# PIC32MZ0512EFF144 device description
Architecture: 32xxxx; Family: PIC32MZEF; Series: PIC32MZ
Registers are 32-bit, read-write, no defined reset value unless marked. A register's access mark holds for its fields unless they carry their own. Offsets are from the block's base; [hi:lo] are bit positions; {n}, {i} and the like mark numbered series; 'fields as' and 'values as' point back to an identical list.

## FUSECONFIG
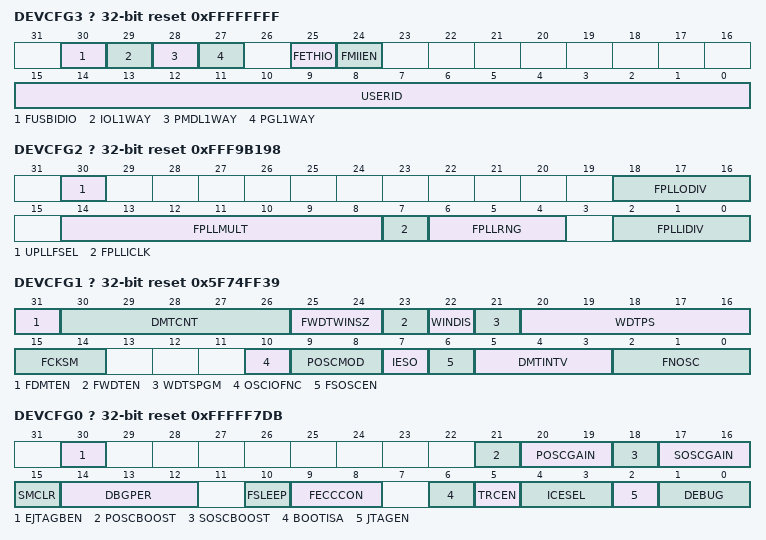
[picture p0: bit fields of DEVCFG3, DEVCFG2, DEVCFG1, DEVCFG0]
? DEVCFG3 size not given access not given reset 0xFFFFFFFF — Device Configuration Word 3
  [30] FUSBIDIO — USB USBID Selection bit
    0=OFF (Controlled by Port Function); 1=ON (Controlled by the USB Module)
  [29] IOL1WAY — Peripheral Pin Select Configuration bit
    1=ON (Allow only one reconfiguration); 0=OFF (Allow multiple reconfigurations)
  [28] PMDL1WAY — Peripheral Module Disable Configuration bit
    values as IOL1WAY
  [27] PGL1WAY — Permission Group Lock One Way Configuration bit
    values as IOL1WAY
  [25] FETHIO — Ethernet I/O Pin Selection Configuration bit
    0=OFF (Alternate Ethernet I/O); 1=ON (Default Ethernet I/O)
  [24] FMIIEN — Ethernet MII Enable Configuration bit
    0=OFF (RMII Enabled); 1=ON (MII Enabled)
  [15:0] USERID
    ?=User ID
? DEVCFG2 size not given access not given reset 0xFFF9B198 — Device Configuration Word 2
  [30] UPLLFSEL — USB PLL Input Frequency Select bit
    1=FREQ_24MHZ (USB PLL input is 24 MHz); 0=FREQ_12MHZ (USB PLL input is 12 MHz)
  [18:16] FPLLODIV — Default System PLL Output Divisor bits
    1=DIV_2 (2x Divider); 2=DIV_4 (4x Divider); 3=DIV_8 (8x Divider); 4=DIV_16 (16x Divider); 7=DIV_32 (32x Divider)
  [14:8] FPLLMULT — System PLL Feedback Divider bits
    {v}=MUL_{v+1} (PLL Multiply by {v+1}) (v=0..127)
  [7] FPLLICLK — System PLL Input Clock Select bit
    1=PLL_FRC (FRC is input to the System PLL); 0=PLL_POSC (POSC is input to the System PLL)
  [6:4] FPLLRNG — System PLL Divided Input Clock Frequency Range bits
    0=RANGE_BYPASS (Bypass); 1=RANGE_5_10_MHZ (5-10 MHz Input); 2=RANGE_8_16_MHZ (8-16 MHz Input); 3=RANGE_13_26_MHZ (13-26 MHz Input); 4=RANGE_21_42_MHZ (21-42 MHz Input); 5=RANGE_34_68_MHZ (34-68 MHz Input)
  [2:0] FPLLIDIV — PLL Input Divider bits
    {v}=DIV_{v+1} ({v+1}x Divider) (v=0..7)
? DEVCFG1 size not given access not given reset 0x5F74FF39 — Device Configuration Word 1
  [31] FDMTEN — Deadman Timer enable bit
    1=ON (Deadman Timer is enabled and cannot be disabled by software); 0=OFF (Deadman Timer is disabled and can be enabled by software)
  [30:26] DMTCNT — Deadman Timer Count Select bits
    0=DMT8 (2^8 (256)); 1=DMT9 (2^9 (512)); 2=DMT10 (2^10 (1024)); 3=DMT11 (2^11 (2048)); 4=DMT12 (2^12 (4096)); 5=DMT13 (2^13 (8192)); 6=DMT14 (2^14 (16384)); 7=DMT15 (2^15 (32768)); 8=DMT16 (2^16 (65536)); 9=DMT17 (2^17 (131072)); 10=DMT18 (2^18 (262144)); 11=DMT19 (2^19 (524288)); 12=DMT20 (2^20 (1048576)); 13=DMT21 (2^21 (2097152)); 14=DMT22 (2^22 (4194304)); 15=DMT23 (2^23 (8388608)); 16=DMT24 (2^24 (16777216)); 17=DMT25 (2^25 (33554432)); 18=DMT26 (2^26 (67108864)); 19=DMT27 (2^27 (134217728)); 20=DMT28 (2^28 (268435456)); 21=DMT29 (2^29 (536870912)); 22=DMT30 (2^30 (1073741824)); 23=DMT31 (2^31 (2147483648))
  [25:24] FWDTWINSZ — Watchdog Timer Window Size bits
    3=WINSZ_25 (Window size is 25%); 2=WINSZ_37 (Window size is 37.5%); 1=WINSZ_50 (Window size is 50%); 0=WINSZ_75 (Window size is 75%)
  [23] FWDTEN — Watchdog Timer Enable bit
    0=OFF (Watchdog Timer is not enabled; it can be enabled in software); 1=ON (Watchdog Timer is enabled and cannot be disabled by software)
  [22] WINDIS — Watchdog Timer Window Enable bit
    1=NORMAL (Watchdog Timer is in non-Window mode); 0=WINDOW (Watchdog Timer is in Window mode)
  [21] WDTSPGM — Watchdog Timer Stop During Flash Programming bit
    0=RUN (WDT runs during Flash programming); 1=STOP (WDT stops during Flash programming)
  [20:16] WDTPS — Watchdog Timer Postscale Select bits
    0=PS1 (1:1); 1=PS2 (1:2); 2=PS4 (1:4); 3=PS8 (1:8); 4=PS16 (1:16); 5=PS32 (1:32); 6=PS64 (1:64); 7=PS128 (1:128); 8=PS256 (1:256); 9=PS512 (1:512); 10=PS1024 (1:1024); 11=PS2048 (1:2048); 12=PS4096 (1:4096); 13=PS8192 (1:8192); 14=PS16384 (1:16384); 15=PS32768 (1:32768); 16=PS65536 (1:65536); 17=PS131072 (1:131072); 18=PS262144 (1:262144); 19=PS524288 (1:524288); 20=PS1048576 (1:1048576)
  [15:14] FCKSM — Clock Switching and Monitoring Selection Configuration bits
    0=CSDCMD (Clock Switch Disabled, FSCM Disabled); 1=CSECMD (Clock Switch Enabled, FSCM Disabled); 2=CSDCME (Clock Switch Disabled, FSCM Enabled); 3=CSECME (Clock Switch Enabled, FSCM Enabled)
  [10] OSCIOFNC — CLKO Enable Configuration bit
    1=OFF (CLKO output disabled); 0=ON (CLKO output signal active on the OSC2 pin)
  [9:8] POSCMOD — Primary Oscillator Configuration bits
    0=EC (EC mode selected); 2=HS (HS Oscillator mode selected); 3=OFF (POSC disabled)
  [7] IESO — Internal External Switchover bit
    0=OFF (Internal External Switchover mode is disabled); 1=ON (Internal External Switchover mode is enabled)
  [6] FSOSCEN — Secondary Oscillator Enable bit
    0=OFF (Disable SOSC); 1=ON (Enable SOSC)
  [5:3] DMTINTV — Deadman Timer Count Window Interval bits
    0=WIN_0 (Window/Interval value is zero); 1=WIN_1_2 (Window/Interval value is 1/2 counter value); 2=WIN_3_4 (Window/Interval value is 3/4 counter value); 3=WIN_7_8 (Window/Interval value is 7/8 counter value); 4=WIN_15_16 (Window/Interval value is 15/16 counter value); 5=WIN_31_32 (Window/Interval value is 31/32 counter value); 6=WIN_63_64 (Window/Interval value is 63/64 counter value); 7=WIN_127_128 (Window/Interval value is 127/128 counter value)
  [2:0] FNOSC — Oscillator Selection bits
    7=FRCDIV (Fast RC Osc w/Div-by-N (FRCDIV)); 1=SPLL (System PLL); 2=POSC (Primary Osc (HS,EC)); 4=SOSC (Low Power Secondary Osc (SOSC)); 5=LPRC (Low Power RC Osc (LPRC))
? DEVCFG0 size not given access not given reset 0xFFFFF7DB — Device Configuration Word 0
  [30] EJTAGBEN — EJTAG Boot Enable bit
    1=NORMAL (Normal EJTAG functionality); 0=REDUCED (Reduced EJTAG functionality)
  [21] POSCBOOST — Primary Oscillator Boost Kick Start Enable bit
    1=ON (Boost the kick start of the oscillator); 0=OFF (Normal start of the oscillator)
  [20:19] POSCGAIN — Primary Oscillator Gain Control bits
    3=GAIN_LEVEL_3 (Gain level 3 (Highest)); 2=GAIN_LEVEL_2; 1=GAIN_LEVEL_1; 0=GAIN_LEVEL_0 (Gain level 0 (Lowest))
  [18] SOSCBOOST — Secondary Oscillator Boost Kick Start Enable bit
    values as POSCBOOST
  [17:16] SOSCGAIN — Secondary Oscillator Gain Control bits
    3=GAIN_LEVEL_3 (Gain Level 3 (highest)); 2=GAIN_LEVEL_2; 0=GAIN_LEVEL_0 (Gain Level 0 (lowest)); 1=GAIN_LEVEL_1
  [15] SMCLR — Soft Master Clear Enable bit
    1=MCLR_NORM (MCLR pin generates a normal system Reset); 0=MCLR_POR (MCLR pin generates an emulated POR Reset)
  [14:12] DBGPER — Debug Mode CPU Access Permission
    4=ALLOW_PG2 (Allow CPU access to Permission Group 2 permission regions); 2=ALLOW_PG1 (Allow CPU access to Permission Group 1 permission regions); 1=ALLOW_PG0 (Allow CPU access to Permission Group 0 permission regions); 3=PG_1_0 (PG0: Allow PG1: Allow PG2: Deny); 5=PG_2_0 (PG0: Allow PG1: Deny PG2: Allow); 6=PG_2_1 (PG0: Deny PG1: Allow PG2: Allow); 7=PG_ALL (Allow CPU access to all permission regions); 0=PG_NONE (Deny CPU access to all permission regions)
  [10] FSLEEP — Flash Sleep Mode bit
    1=OFF (Flash is powered down when the device is in Sleep mode); 0=VREGS (Flash power down is controlled by the VREGS bit)
  [9:8] FECCCON — Dynamic Flash ECC Configuration bits
    0=ON (Flash ECC is enabled (ECCCON bits are locked)); 1=DYNAMIC (Dynamic Flash ECC is enabled (ECCCON bits are locked)); 2=OFF_LOCKED (ECC and Dynamic ECC are disabled (ECCCON bits are locked)); 3=OFF_UNLOCKED (ECC and Dynamic ECC are disabled (ECCCON bits are writable))
  [6] BOOTISA — Boot ISA Selection bit
    1=MIPS32 (Boot code and Exception code is MIPS32); 0=MICROMIPS (Boot code and Exception code is microMIPS)
  [5] TRCEN — Trace Enable bit
    1=ON (Trace features in the CPU are enabled); 0=OFF (Trace features in the CPU are disabled)
  [4:3] ICESEL — In-Circuit Emulator/Debugger Communication Channel Select bits
    3=ICS_PGx1 (PGEC1/PGED1 pair is used); 2=ICS_PGx2 (PGEC2/PGED2 pair is used)
  [2] JTAGEN — JTAG Enable bit
    1=ON (JTAG Port Enabled); 0=OFF (JTAG Disabled)
  [1:0] DEBUG — Background Debugger Enable bits
    0=ON (Debugger is enabled); 3=OFF (Debugger is disabled)
? DEVCP0 size not given access not given reset 0xFFFFFFFF — Device Code-Protect 0 Register
  [28] CP — Code-Protect bit
    0=ON (Protection Enabled); 1=OFF (Protection Disabled)
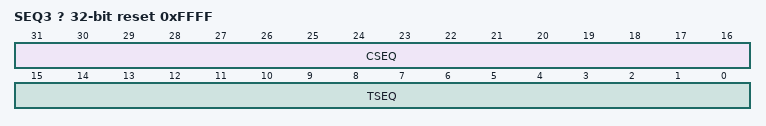
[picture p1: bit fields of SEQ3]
? SEQ3 size not given access not given reset 0xFFFF — Sequence Word 3 Register
  [31:16] CSEQ — Boot Flash Complement Sequence Number bits
    ?=Boot Flash Complement Sequence Number
  [15:0] TSEQ — Boot Flash True Sequence Number bits
    ?=Boot Flash True Sequence Number

## Notices in the file
Copyright (c) 2017 Microchip Technology Inc.
SPDX-License-Identifier: Apache-2.0
Licensed under the Apache License, Version 2.0 (the "License");
you may not use this file except in compliance with the License.
You may obtain a copy of the License at
http://www.apache.org/licenses/LICENSE-2.0
Unless required by applicable law or agreed to in writing, software
distributed under the License is distributed on an "AS IS" BASIS,
WITHOUT WARRANTIES OR CONDITIONS OF ANY KIND, either express or implied.
See the License for the specific language governing permissions and
limitations under the License.
